AUTOSAR XML (schema 3.1.2)
package /Components/SWC_UsThrMT
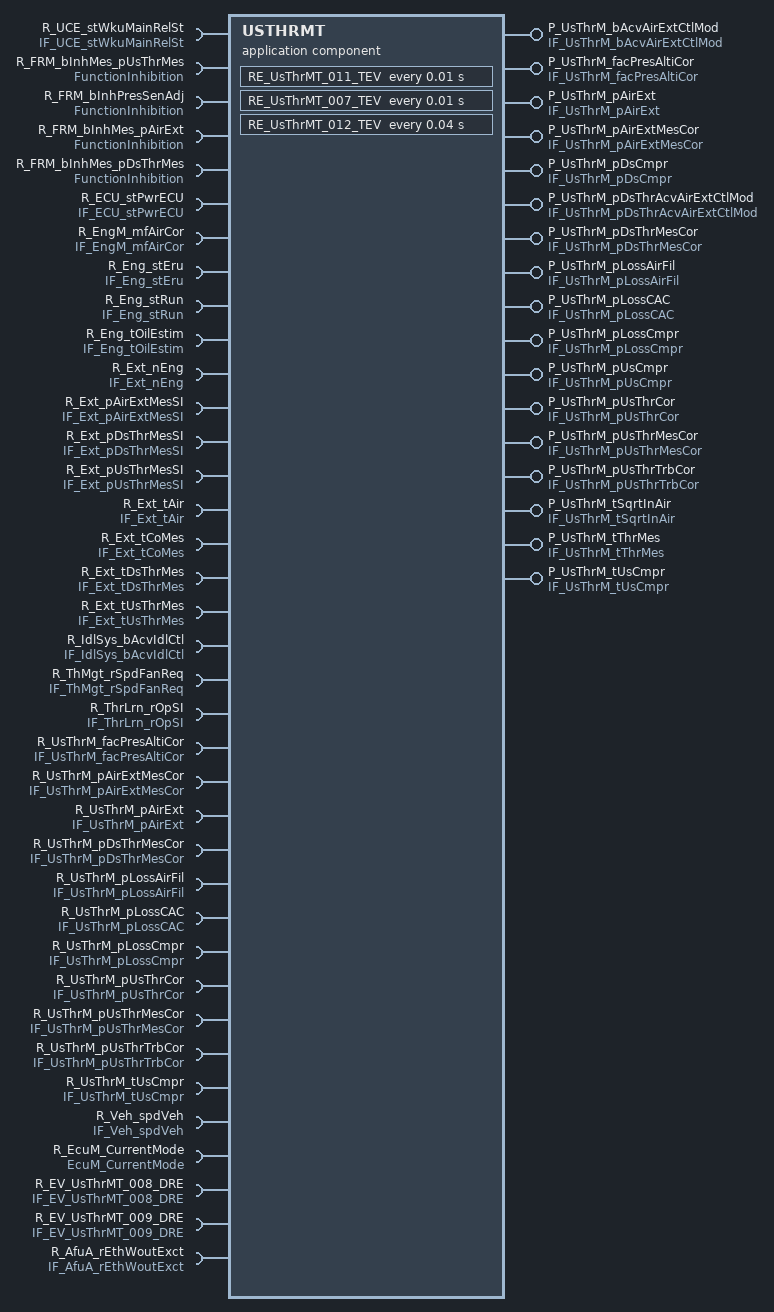
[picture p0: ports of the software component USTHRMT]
  application software component type USTHRMT  # UsThrMT
    5 x require port:
      R_UCE_stWkuMainRelSt: required-interface=IF_UCE_stWkuMainRelSt
      R_FRM_bInhMes_pUsThrMes: required-interface=FunctionInhibition
      R_FRM_bInhPresSenAdj: required-interface=FunctionInhibition
      R_FRM_bInhMes_pAirExt: required-interface=FunctionInhibition
      R_FRM_bInhMes_pDsThrMes: required-interface=FunctionInhibition
    17 x provide port:
      P_UsThrM_bAcvAirExtCtlMod: unqueued-sender-com-spec{data-element=UsThrM_bAcvAirExtCtlMod, can-invalidate=false, init-value=ConstantValue}, provided-interface=IF_UsThrM_bAcvAirExtCtlMod
      P_UsThrM_facPresAltiCor: unqueued-sender-com-spec{data-element=UsThrM_facPresAltiCor, can-invalidate=false, init-value=ConstantValue1}, provided-interface=IF_UsThrM_facPresAltiCor
      P_UsThrM_pAirExt: unqueued-sender-com-spec{data-element=UsThrM_pAirExt, can-invalidate=false, init-value=ConstantValue3}, provided-interface=IF_UsThrM_pAirExt
      P_UsThrM_pAirExtMesCor: unqueued-sender-com-spec{data-element=UsThrM_pAirExtMesCor, can-invalidate=false, init-value=UInt16InitValue}, provided-interface=IF_UsThrM_pAirExtMesCor
      P_UsThrM_pDsCmpr: unqueued-sender-com-spec{data-element=UsThrM_pDsCmpr, can-invalidate=false, init-value=UInt16InitValue5}, provided-interface=IF_UsThrM_pDsCmpr
      P_UsThrM_pDsThrAcvAirExtCtlMod: unqueued-sender-com-spec{data-element=UsThrM_pDsThrAcvAirExtCtlMod, can-invalidate=false, init-value=UInt16InitValue7}, provided-interface=IF_UsThrM_pDsThrAcvAirExtCtlMod
      P_UsThrM_pDsThrMesCor: unqueued-sender-com-spec{data-element=UsThrM_pDsThrMesCor, can-invalidate=false, init-value=ConstantValue9}, provided-interface=IF_UsThrM_pDsThrMesCor
      P_UsThrM_pLossAirFil: unqueued-sender-com-spec{data-element=UsThrM_pLossAirFil, can-invalidate=false, init-value=UInt16InitValue11}, provided-interface=IF_UsThrM_pLossAirFil
      P_UsThrM_pLossCAC: unqueued-sender-com-spec{data-element=UsThrM_pLossCAC, can-invalidate=false, init-value=ConstantValue13}, provided-interface=IF_UsThrM_pLossCAC
      P_UsThrM_pLossCmpr: unqueued-sender-com-spec{data-element=UsThrM_pLossCmpr, can-invalidate=false, init-value=SInt16InitValue}, provided-interface=IF_UsThrM_pLossCmpr
      P_UsThrM_pUsCmpr: unqueued-sender-com-spec{data-element=UsThrM_pUsCmpr, can-invalidate=false, init-value=ConstantValue15}, provided-interface=IF_UsThrM_pUsCmpr
      P_UsThrM_pUsThrCor: unqueued-sender-com-spec{data-element=UsThrM_pUsThrCor, can-invalidate=false, init-value=ConstantValue17}, provided-interface=IF_UsThrM_pUsThrCor
      P_UsThrM_pUsThrMesCor: unqueued-sender-com-spec{data-element=UsThrM_pUsThrMesCor, can-invalidate=false, init-value=UInt16InitValue19}, provided-interface=IF_UsThrM_pUsThrMesCor
      P_UsThrM_pUsThrTrbCor: unqueued-sender-com-spec{data-element=UsThrM_pUsThrTrbCor, can-invalidate=false, init-value=UInt16InitValue21}, provided-interface=IF_UsThrM_pUsThrTrbCor
      P_UsThrM_tSqrtInAir: unqueued-sender-com-spec{data-element=UsThrM_tSqrtInAir, can-invalidate=false, init-value=ConstantValue23}, provided-interface=IF_UsThrM_tSqrtInAir
      P_UsThrM_tThrMes: unqueued-sender-com-spec{data-element=UsThrM_tThrMes, can-invalidate=false, init-value=ConstantValue25}, provided-interface=IF_UsThrM_tThrMes
      P_UsThrM_tUsCmpr: unqueued-sender-com-spec{data-element=UsThrM_tUsCmpr, can-invalidate=false, init-value=ConstantValue27}, provided-interface=IF_UsThrM_tUsCmpr
    32 x require port:
      R_ECU_stPwrECU: unqueued-receiver-com-spec{data-element=ECU_stPwrECU, init-value=UInt8InitValue, resync-time=0}, required-interface=IF_ECU_stPwrECU
      R_EngM_mfAirCor: unqueued-receiver-com-spec{data-element=EngM_mfAirCor, init-value=ConstantValue29, resync-time=0}, required-interface=IF_EngM_mfAirCor
      R_Eng_stEru: unqueued-receiver-com-spec{data-element=Eng_stEru, init-value=ConstantValue31, resync-time=0}, required-interface=IF_Eng_stEru
      R_Eng_stRun: unqueued-receiver-com-spec{data-element=Eng_stRun, init-value=UInt8InitValue33, resync-time=0}, required-interface=IF_Eng_stRun
      R_Eng_tOilEstim: unqueued-receiver-com-spec{data-element=Eng_tOilEstim, init-value=ConstantValue35, resync-time=0}, required-interface=IF_Eng_tOilEstim
      R_Ext_nEng: unqueued-receiver-com-spec{data-element=Ext_nEng, init-value=ConstantValue37, resync-time=0}, required-interface=IF_Ext_nEng
      R_Ext_pAirExtMesSI: unqueued-receiver-com-spec{data-element=Ext_pAirExtMesSI, init-value=UInt16InitValue39, resync-time=0}, required-interface=IF_Ext_pAirExtMesSI
      R_Ext_pDsThrMesSI: unqueued-receiver-com-spec{data-element=Ext_pDsThrMesSI, init-value=ConstantValue41, resync-time=0}, required-interface=IF_Ext_pDsThrMesSI
      R_Ext_pUsThrMesSI: unqueued-receiver-com-spec{data-element=Ext_pUsThrMesSI, init-value=UInt16InitValue43, resync-time=0}, required-interface=IF_Ext_pUsThrMesSI
      R_Ext_tAir: unqueued-receiver-com-spec{data-element=Ext_tAir, init-value=ConstantValue45, resync-time=0}, required-interface=IF_Ext_tAir
      R_Ext_tCoMes: unqueued-receiver-com-spec{data-element=Ext_tCoMes, init-value=ConstantValue47, resync-time=0}, required-interface=IF_Ext_tCoMes
      R_Ext_tDsThrMes: unqueued-receiver-com-spec{data-element=Ext_tDsThrMes, init-value=ConstantValue49, resync-time=0}, required-interface=IF_Ext_tDsThrMes
      R_Ext_tUsThrMes: unqueued-receiver-com-spec{data-element=Ext_tUsThrMes, init-value=ConstantValue51, resync-time=0}, required-interface=IF_Ext_tUsThrMes
      R_IdlSys_bAcvIdlCtl: unqueued-receiver-com-spec{data-element=IdlSys_bAcvIdlCtl, init-value=ConstantValue53, resync-time=0}, required-interface=IF_IdlSys_bAcvIdlCtl
      R_ThMgt_rSpdFanReq: unqueued-receiver-com-spec{data-element=ThMgt_rSpdFanReq, init-value=ConstantValue55, resync-time=0}, required-interface=IF_ThMgt_rSpdFanReq
      R_ThrLrn_rOpSI: unqueued-receiver-com-spec{data-element=ThrLrn_rOpSI, init-value=ConstantValue57, resync-time=0}, required-interface=IF_ThrLrn_rOpSI
      R_UsThrM_facPresAltiCor: unqueued-receiver-com-spec{data-element=UsThrM_facPresAltiCor, init-value=ConstantValue59, resync-time=0}, required-interface=IF_UsThrM_facPresAltiCor
      R_UsThrM_pAirExtMesCor: unqueued-receiver-com-spec{data-element=UsThrM_pAirExtMesCor, init-value=UInt16InitValue, resync-time=0}, required-interface=IF_UsThrM_pAirExtMesCor
      R_UsThrM_pAirExt: unqueued-receiver-com-spec{data-element=UsThrM_pAirExt, init-value=ConstantValue61, resync-time=0}, required-interface=IF_UsThrM_pAirExt
      R_UsThrM_pDsThrMesCor: unqueued-receiver-com-spec{data-element=UsThrM_pDsThrMesCor, init-value=ConstantValue63, resync-time=0}, required-interface=IF_UsThrM_pDsThrMesCor
      R_UsThrM_pLossAirFil: unqueued-receiver-com-spec{data-element=UsThrM_pLossAirFil, init-value=UInt16InitValue65, resync-time=0}, required-interface=IF_UsThrM_pLossAirFil
      R_UsThrM_pLossCAC: unqueued-receiver-com-spec{data-element=UsThrM_pLossCAC, init-value=ConstantValue67, resync-time=0}, required-interface=IF_UsThrM_pLossCAC
      R_UsThrM_pLossCmpr: unqueued-receiver-com-spec{data-element=UsThrM_pLossCmpr, init-value=SInt16InitValue, resync-time=0}, required-interface=IF_UsThrM_pLossCmpr
      R_UsThrM_pUsThrCor: unqueued-receiver-com-spec{data-element=UsThrM_pUsThrCor, init-value=ConstantValue69, resync-time=0}, required-interface=IF_UsThrM_pUsThrCor
      R_UsThrM_pUsThrMesCor: unqueued-receiver-com-spec{data-element=UsThrM_pUsThrMesCor, init-value=UInt16InitValue71, resync-time=0}, required-interface=IF_UsThrM_pUsThrMesCor
      R_UsThrM_pUsThrTrbCor: unqueued-receiver-com-spec{data-element=UsThrM_pUsThrTrbCor, init-value=UInt16InitValue73, resync-time=0}, required-interface=IF_UsThrM_pUsThrTrbCor
      R_UsThrM_tUsCmpr: unqueued-receiver-com-spec{data-element=UsThrM_tUsCmpr, init-value=ConstantValue75, resync-time=0}, required-interface=IF_UsThrM_tUsCmpr
      R_Veh_spdVeh: unqueued-receiver-com-spec{data-element=Veh_spdVeh, init-value=ConstantValue77, resync-time=0}, required-interface=IF_Veh_spdVeh
      R_EcuM_CurrentMode: required-interface=EcuM_CurrentMode
      R_EV_UsThrMT_008_DRE: unqueued-receiver-com-spec{data-element=EV_UsThrMT_008_DRE, init-value=UInt8InitValue79, resync-time=0}, required-interface=IF_EV_UsThrMT_008_DRE
      R_EV_UsThrMT_009_DRE: unqueued-receiver-com-spec{data-element=EV_UsThrMT_009_DRE, init-value=UInt8InitValue81, resync-time=0}, required-interface=IF_EV_UsThrMT_009_DRE
      R_AfuA_rEthWoutExct: unqueued-receiver-com-spec{data-element=AfuA_rEthWoutExct, init-value=ConstantValue2, resync-time=0}, required-interface=IF_AfuA_rEthWoutExct
  56 x constant specification:
    ConstantValue
      value:
        boolean literal ConstantValue: type=DT_UsThrM_bAcvAirExtCtlMod, value=false
    ConstantValue1
      value:
        integer literal ConstantValue1: type=DT_UsThrM_facPresAltiCor, value=0
    ConstantValue13
      value:
        integer literal ConstantValue13: type=DT_UsThrM_pLossCAC, value=0
    ConstantValue15
      value:
        integer literal ConstantValue15: type=DT_UsThrM_pUsCmpr, value=0
    ConstantValue17
      value:
        integer literal ConstantValue17: type=DT_UsThrM_pUsThrCor, value=0
    ConstantValue2
      value:
        integer literal ConstantValue2: type=DT_AfuA_rEthWoutExct, value=0
    ConstantValue23
      value:
        integer literal ConstantValue23: type=DT_UsThrM_tSqrtInAir, value=120
    ConstantValue25
      value:
        integer literal ConstantValue25: type=DT_UsThrM_tThrMes, value=0
    ConstantValue27
      value:
        integer literal ConstantValue27: type=DT_UsThrM_tUsCmpr, value=0
    ConstantValue29
      value:
        integer literal ConstantValue29: type=DT_EngM_mfAirCor, value=0
    ConstantValue3
      value:
        integer literal ConstantValue3: type=DT_UsThrM_pAirExt, value=0
    ConstantValue31
      value:
        integer literal ConstantValue31: type=DT_Eng_stEru, value=1
    ConstantValue35
      value:
        integer literal ConstantValue35: type=DT_Eng_tOilEstim, value=0
    ConstantValue37
      value:
        integer literal ConstantValue37: type=DT_Ext_nEng, value=0
    ConstantValue41
      value:
        integer literal ConstantValue41: type=DT_Ext_pDsThrMesSI, value=1875
    ConstantValue45
      value:
        integer literal ConstantValue45: type=DT_Ext_tAir, value=20
    ConstantValue47
      value:
        integer literal ConstantValue47: type=DT_Ext_tCoMes, value=20
    ConstantValue49
      value:
        integer literal ConstantValue49: type=DT_Ext_tDsThrMes, value=25
    ConstantValue51
      value:
        integer literal ConstantValue51: type=DT_Ext_tUsThrMes, value=25
    ConstantValue53
      value:
        boolean literal ConstantValue53: type=DT_IdlSys_bAcvIdlCtl, value=false
    ConstantValue55
      value:
        integer literal ConstantValue55: type=DT_ThMgt_rSpdFanReq, value=0
    ConstantValue57
      value:
        integer literal ConstantValue57: type=DT_ThrLrn_rOpSI, value=0
    ConstantValue59
      value:
        integer literal ConstantValue59: type=DT_UsThrM_facPresAltiCor, value=0
    ConstantValue61
      value:
        integer literal ConstantValue61: type=DT_UsThrM_pAirExt, value=0
    ConstantValue63
      value:
        integer literal ConstantValue63: type=DT_UsThrM_pDsThrMesCor, value=0
    ConstantValue67
      value:
        integer literal ConstantValue67: type=DT_UsThrM_pLossCAC, value=0
    ConstantValue69
      value:
        integer literal ConstantValue69: type=DT_UsThrM_pUsThrCor, value=0
    ConstantValue75
      value:
        integer literal ConstantValue75: type=DT_UsThrM_tUsCmpr, value=0
    ConstantValue77
      value:
        integer literal ConstantValue77: type=DT_Veh_spdVeh, value=0
    ConstantValue9
      value:
        integer literal ConstantValue9: type=DT_UsThrM_pDsThrMesCor, value=0
    InitValue_UInt16_0
      value:
        integer literal InitValue_UInt16_0: type=DT_UsThrM_tiTmrDifPres_irv, value=0
    InitValue_UInt16_085
      value:
        integer literal InitValue_UInt16_085: type=DT_UsThrM_ctUpdAirExtPresCut_irv, value=0
    InitValue_UInt16_087
      value:
        integer literal InitValue_UInt16_087: type=DT_UsThrM_ctUpdAirExtPresIdl_irv, value=0
    InitValue_UInt16_089
      value:
        integer literal InitValue_UInt16_089: type=DT_UsThrM_pUsThrMesSIFil_irv, value=0
    InitValue_UInt16_091
      value:
        integer literal InitValue_UInt16_091: type=DT_UsThrM_pAirExtMesSIFil_irv, value=0
    InitValue_UInt16_093
      value:
        integer literal InitValue_UInt16_093: type=DT_UsThrM_ctUpdAirExtPresRun_irv, value=0
    InitValue_UInt16_095
      value:
        integer literal InitValue_UInt16_095: type=DT_UsThrM_pDsThrMesSIFil_irv, value=0
    InitValue_UInt16_097
      value:
        integer literal InitValue_UInt16_097: type=DT_UsThrM_pAirExtRaw_irv, value=0
    InitValue_UInt16_099
      value:
        integer literal InitValue_UInt16_099: type=DT_UsThrM_ctUpdAirExtPresStall_irv, value=0
    InitValue_UInt32_0
      value:
        integer literal InitValue_UInt32_0: type=DT_UsThrM_tUndHo_irv, value=0
    SInt16InitValue
      value:
        integer literal SInt16InitValue: type=DT_UsThrM_pLossCmpr, value=-32768
    UInt16InitValue
      value:
        integer literal UInt16InitValue: type=DT_UsThrM_pAirExtMesCor, value=0
    UInt16InitValue11
      value:
        integer literal UInt16InitValue11: type=DT_UsThrM_pLossAirFil, value=0
    UInt16InitValue19
      value:
        integer literal UInt16InitValue19: type=DT_UsThrM_pUsThrMesCor, value=0
    UInt16InitValue21
      value:
        integer literal UInt16InitValue21: type=DT_UsThrM_pUsThrTrbCor, value=0
    UInt16InitValue39
      value:
        integer literal UInt16InitValue39: type=DT_Ext_pAirExtMesSI, value=0
    UInt16InitValue43
      value:
        integer literal UInt16InitValue43: type=DT_Ext_pUsThrMesSI, value=0
    UInt16InitValue5
      value:
        integer literal UInt16InitValue5: type=DT_UsThrM_pDsCmpr, value=0
    UInt16InitValue65
      value:
        integer literal UInt16InitValue65: type=DT_UsThrM_pLossAirFil, value=0
    UInt16InitValue7
      value:
        integer literal UInt16InitValue7: type=DT_UsThrM_pDsThrAcvAirExtCtlMod, value=0
    UInt16InitValue71
      value:
        integer literal UInt16InitValue71: type=DT_UsThrM_pUsThrMesCor, value=0
    UInt16InitValue73
      value:
        integer literal UInt16InitValue73: type=DT_UsThrM_pUsThrTrbCor, value=0
    UInt8InitValue
      value:
        integer literal UInt8InitValue: type=DT_ECU_stPwrECU, value=1
    UInt8InitValue33
      value:
        integer literal UInt8InitValue33: type=DT_Eng_stRun, value=1
    UInt8InitValue79
      value:
        integer literal UInt8InitValue79: type=DT_EV_UsThrMT_008_DRE, value=0
    UInt8InitValue81
      value:
        integer literal UInt8InitValue81: type=DT_EV_UsThrMT_009_DRE, value=0
  internal behavior IB_UsThrMT: component=USTHRMT
    timing event EV_UsThrMT_011_TEV: mode-dependency=dependent-on-mode=[R_UCE_stWkuMainRelSt.RCD_stWkuMainRelSt.PreMainWakeUp, R_UCE_stWkuMainRelSt.RCD_stWkuMainRelSt.PostMainWakeUp, R_UCE_stWkuMainRelSt.RCD_stWkuMainRelSt.Invalid], start-on-event=RE_UsThrMT_011_TEV, period=0.01
    data received event EV_UsThrMT_009_DRE: mode-dependency=dependent-on-mode=[R_UCE_stWkuMainRelSt.RCD_stWkuMainRelSt.PreMainWakeUp, R_UCE_stWkuMainRelSt.RCD_stWkuMainRelSt.PostMainWakeUp, R_UCE_stWkuMainRelSt.RCD_stWkuMainRelSt.Invalid], start-on-event=RE_UsThrMT_009_DRE, data=R_EV_UsThrMT_009_DRE.EV_UsThrMT_009_DRE
    mode switch event EV_UsThrMT_001_MSE: start-on-event=RE_UsThrMT_001_MSE, activation=ENTRY, mode=R_EcuM_CurrentMode.currentMode.RUN
    5 x timing event, all with mode-dependency=dependent-on-mode=[R_UCE_stWkuMainRelSt.RCD_stWkuMainRelSt.PreMainWakeUp, R_UCE_stWkuMainRelSt.RCD_stWkuMainRelSt.PostMainWakeUp, R_UCE_stWkuMainRelSt.RCD_stWkuMainRelSt.Invalid]:
      EV_UsThrMT_005_TEV: start-on-event=RE_UsThrMT_005_TEV, period=0.04
      EV_UsThrMT_008_TEV: start-on-event=RE_UsThrMT_008_TEV, period=0.04
      EV_UsThrMT_006_TEV: start-on-event=RE_UsThrMT_006_TEV, period=0.01
      EV_UsThrMT_002_TEV: start-on-event=RE_UsThrMT_002_TEV, period=0.01
      EV_UsThrMT_010_TEV: start-on-event=RE_UsThrMT_010_TEV, period=0.01
    data received event EV_UsThrMT_008_DRE: mode-dependency=dependent-on-mode=[R_UCE_stWkuMainRelSt.RCD_stWkuMainRelSt.PreMainWakeUp, R_UCE_stWkuMainRelSt.RCD_stWkuMainRelSt.PostMainWakeUp, R_UCE_stWkuMainRelSt.RCD_stWkuMainRelSt.Invalid], start-on-event=RE_UsThrMT_008_DRE, data=R_EV_UsThrMT_008_DRE.EV_UsThrMT_008_DRE
    mode switch event EV_UsThrMT_004_MSE: start-on-event=RE_UsThrMT_004_MSE, activation=ENTRY, mode=R_EcuM_CurrentMode.currentMode.RUN
    timing event EV_UsThrMT_007_TEV: mode-dependency=dependent-on-mode=[R_UCE_stWkuMainRelSt.RCD_stWkuMainRelSt.PreMainWakeUp, R_UCE_stWkuMainRelSt.RCD_stWkuMainRelSt.PostMainWakeUp, R_UCE_stWkuMainRelSt.RCD_stWkuMainRelSt.Invalid], start-on-event=RE_UsThrMT_007_TEV, period=0.01
    timing event EV_UsThrMT_012_TEV: mode-dependency=dependent-on-mode=[R_UCE_stWkuMainRelSt.RCD_stWkuMainRelSt.PreMainWakeUp, R_UCE_stWkuMainRelSt.RCD_stWkuMainRelSt.PostMainWakeUp, R_UCE_stWkuMainRelSt.RCD_stWkuMainRelSt.Invalid], start-on-event=RE_UsThrMT_012_TEV, period=0.04
    10 x inter runnable variable, all with sw-calibration-access=READ-WRITE, communication-approach=EXPLICIT:
      UsThrM_ctUpdAirExtPresIdl_irv: type=DT_UsThrM_ctUpdAirExtPresIdl_irv, init-value=InitValue_UInt16_087
      UsThrM_pDsThrMesSIFil_irv: type=DT_UsThrM_pDsThrMesSIFil_irv, init-value=InitValue_UInt16_095
      UsThrM_ctUpdAirExtPresRun_irv: type=DT_UsThrM_ctUpdAirExtPresRun_irv, init-value=InitValue_UInt16_093
      UsThrM_tUndHo_irv: type=DT_UsThrM_tUndHo_irv, init-value=InitValue_UInt32_0
      UsThrM_ctUpdAirExtPresStall_irv: type=DT_UsThrM_ctUpdAirExtPresStall_irv, init-value=InitValue_UInt16_099
      UsThrM_pAirExtMesSIFil_irv: type=DT_UsThrM_pAirExtMesSIFil_irv, init-value=InitValue_UInt16_091
      UsThrM_tiTmrDifPres_irv: type=DT_UsThrM_tiTmrDifPres_irv, init-value=InitValue_UInt16_0
      UsThrM_pUsThrMesSIFil_irv: type=DT_UsThrM_pUsThrMesSIFil_irv, init-value=InitValue_UInt16_089
      UsThrM_pAirExtRaw_irv: type=DT_UsThrM_pAirExtRaw_irv, init-value=InitValue_UInt16_097
      UsThrM_ctUpdAirExtPresCut_irv: type=DT_UsThrM_ctUpdAirExtPresCut_irv, init-value=InitValue_UInt16_085
    12 x runnable:
      RE_UsThrMT_008_TEV
        data receive point dr_EngM_mfAirCor: data-element=R_EngM_mfAirCor.EngM_mfAirCor
        data send point DSP_P_UsThrM_pAirExt_UsThrM_pAirExt: data-element=P_UsThrM_pAirExt.UsThrM_pAirExt
        data send point ds_UsThrM_pLossAirFil: data-element=P_UsThrM_pLossAirFil.UsThrM_pLossAirFil
      RE_UsThrMT_010_TEV: read-variable=[UsThrM_ctUpdAirExtPresIdl_irv, UsThrM_ctUpdAirExtPresCut_irv, UsThrM_ctUpdAirExtPresRun_irv, UsThrM_ctUpdAirExtPresStall_irv, UsThrM_pAirExtRaw_irv], written-variable=[UsThrM_ctUpdAirExtPresIdl_irv, UsThrM_ctUpdAirExtPresCut_irv, UsThrM_ctUpdAirExtPresRun_irv, UsThrM_ctUpdAirExtPresStall_irv, UsThrM_pAirExtRaw_irv]
        13 x data receive point:
          dr_IdlSys_bAcvIdlCtl: data-element=R_IdlSys_bAcvIdlCtl.IdlSys_bAcvIdlCtl
          dr_ECU_stPwrECU: data-element=R_ECU_stPwrECU.ECU_stPwrECU
          dr_UsThrM_pUsThrMesCor: data-element=R_UsThrM_pUsThrMesCor.UsThrM_pUsThrMesCor
          dr_Eng_stEru: data-element=R_Eng_stEru.Eng_stEru
          dr_UsThrM_pLossCmpr: data-element=R_UsThrM_pLossCmpr.UsThrM_pLossCmpr
          dr_UsThrM_pDsThrMesCor: data-element=R_UsThrM_pDsThrMesCor.UsThrM_pDsThrMesCor
          dr_Eng_stRun: data-element=R_Eng_stRun.Eng_stRun
          dr_UsThrM_pLossAirFil: data-element=R_UsThrM_pLossAirFil.UsThrM_pLossAirFil
          dr_Ext_nEng: data-element=R_Ext_nEng.Ext_nEng
          dr_UsThrM_pAirExt: data-element=R_UsThrM_pAirExt.UsThrM_pAirExt
          dr_ThrLrn_rOpSI: data-element=R_ThrLrn_rOpSI.ThrLrn_rOpSI
          dr_UsThrM_pLossCAC: data-element=R_UsThrM_pLossCAC.UsThrM_pLossCAC
          dr_UsThrM_pAirExtMesCor: data-element=R_UsThrM_pAirExtMesCor.UsThrM_pAirExtMesCor
        data send point ds_UsThrM_facPresAltiCor: data-element=P_UsThrM_facPresAltiCor.UsThrM_facPresAltiCor
        sync call ssp_FRM_bInhMes_pDsThrMes: operation=R_FRM_bInhMes_pDsThrMes.GetFunctionPermission
        sync call ssp_FRM_bInhMes_pAirExt: operation=R_FRM_bInhMes_pAirExt.GetFunctionPermission
        sync call ssp_FRM_bInhMes_pUsThrMes: operation=R_FRM_bInhMes_pUsThrMes.GetFunctionPermission
      RE_UsThrMT_006_TEV
        4 x data receive point:
          dr_UsThrM_pLossAirFil: data-element=R_UsThrM_pLossAirFil.UsThrM_pLossAirFil
          dr_EngM_mfAirCor: data-element=R_EngM_mfAirCor.EngM_mfAirCor
          dr_UsThrM_pAirExt: data-element=R_UsThrM_pAirExt.UsThrM_pAirExt
          dr_UsThrM_pUsThrMesCor: data-element=R_UsThrM_pUsThrMesCor.UsThrM_pUsThrMesCor
        5 x data send point:
          ds_UsThrM_pLossCAC: data-element=P_UsThrM_pLossCAC.UsThrM_pLossCAC
          ds_UsThrM_pLossCmpr: data-element=P_UsThrM_pLossCmpr.UsThrM_pLossCmpr
          ds_UsThrM_pDsCmpr: data-element=P_UsThrM_pDsCmpr.UsThrM_pDsCmpr
          ds_UsThrM_pUsCmpr: data-element=P_UsThrM_pUsCmpr.UsThrM_pUsCmpr
          ds_UsThrM_pUsThrTrbCor: data-element=P_UsThrM_pUsThrTrbCor.UsThrM_pUsThrTrbCor
        sync call ssp_FRM_bInhMes_pUsThrMes: operation=R_FRM_bInhMes_pUsThrMes.GetFunctionPermission
      RE_UsThrMT_002_TEV: read-variable=[UsThrM_pDsThrMesSIFil_irv, UsThrM_pAirExtMesSIFil_irv, UsThrM_tiTmrDifPres_irv, UsThrM_pUsThrMesSIFil_irv], written-variable=[UsThrM_pDsThrMesSIFil_irv, UsThrM_pAirExtMesSIFil_irv, UsThrM_tiTmrDifPres_irv, UsThrM_pUsThrMesSIFil_irv]
        4 x data receive point:
          dr_Ext_pDsThrMesSI: data-element=R_Ext_pDsThrMesSI.Ext_pDsThrMesSI
          dr_Ext_pAirExtMesSI: data-element=R_Ext_pAirExtMesSI.Ext_pAirExtMesSI
          dr_Eng_stEru: data-element=R_Eng_stEru.Eng_stEru
          dr_Ext_pUsThrMesSI: data-element=R_Ext_pUsThrMesSI.Ext_pUsThrMesSI
        data send point ds_UsThrM_pAirExtMesCor: data-element=P_UsThrM_pAirExtMesCor.UsThrM_pAirExtMesCor
        data send point ds_UsThrM_pDsThrMesCor: data-element=P_UsThrM_pDsThrMesCor.UsThrM_pDsThrMesCor
        data send point ds_UsThrM_pUsThrMesCor: data-element=P_UsThrM_pUsThrMesCor.UsThrM_pUsThrMesCor
        sync call ssp_FRM_bInhPresSenAdj: operation=R_FRM_bInhPresSenAdj.GetFunctionPermission
      RE_UsThrMT_004_MSE: written-variable=[UsThrM_tUndHo_irv, UsThrM_ctUpdAirExtPresRun_irv, UsThrM_ctUpdAirExtPresIdl_irv, UsThrM_ctUpdAirExtPresCut_irv, UsThrM_ctUpdAirExtPresStall_irv, UsThrM_pAirExtRaw_irv]
        6 x data receive point:
          dr_UsThrM_pAirExt: data-element=R_UsThrM_pAirExt.UsThrM_pAirExt
          dr_Ext_tUsThrMes: data-element=R_Ext_tUsThrMes.Ext_tUsThrMes
          dr_Ext_tDsThrMes: data-element=R_Ext_tDsThrMes.Ext_tDsThrMes
          dr_UsThrM_pUsThrTrbCor: data-element=R_UsThrM_pUsThrTrbCor.UsThrM_pUsThrTrbCor
          dr_UsThrM_pUsThrMesCor: data-element=R_UsThrM_pUsThrMesCor.UsThrM_pUsThrMesCor
          dr_UsThrM_pAirExtMesCor: data-element=R_UsThrM_pAirExtMesCor.UsThrM_pAirExtMesCor
        14 x data send point:
          ds_UsThrM_pLossCmpr: data-element=P_UsThrM_pLossCmpr.UsThrM_pLossCmpr
          ds_UsThrM_pUsThrCor: data-element=P_UsThrM_pUsThrCor.UsThrM_pUsThrCor
          ds_UsThrM_pUsThrTrbCor: data-element=P_UsThrM_pUsThrTrbCor.UsThrM_pUsThrTrbCor
          ds_UsThrM_tThrMes: data-element=P_UsThrM_tThrMes.UsThrM_tThrMes
          ds_UsThrM_bAcvAirExtCtlMod: data-element=P_UsThrM_bAcvAirExtCtlMod.UsThrM_bAcvAirExtCtlMod
          ds_UsThrM_tSqrtInAir: data-element=P_UsThrM_tSqrtInAir.UsThrM_tSqrtInAir
          ds_UsThrM_pDsThrAcvAirExtCtlMod: data-element=P_UsThrM_pDsThrAcvAirExtCtlMod.UsThrM_pDsThrAcvAirExtCtlMod
          ds_UsThrM_pLossCAC: data-element=P_UsThrM_pLossCAC.UsThrM_pLossCAC
          ds_UsThrM_tUsCmpr: data-element=P_UsThrM_tUsCmpr.UsThrM_tUsCmpr
          ds_UsThrM_facPresAltiCor: data-element=P_UsThrM_facPresAltiCor.UsThrM_facPresAltiCor
          ds_UsThrM_pUsCmpr: data-element=P_UsThrM_pUsCmpr.UsThrM_pUsCmpr
          DSP_P_UsThrM_pAirExt_UsThrM_pAirExt: data-element=P_UsThrM_pAirExt.UsThrM_pAirExt
          ds_UsThrM_pLossAirFil: data-element=P_UsThrM_pLossAirFil.UsThrM_pLossAirFil
          ds_UsThrM_pDsCmpr: data-element=P_UsThrM_pDsCmpr.UsThrM_pDsCmpr
        sync call ssp_FRM_bInhMes_pAirExt: operation=R_FRM_bInhMes_pAirExt.GetFunctionPermission
      RE_UsThrMT_001_MSE: written-variable=[UsThrM_pAirExtMesSIFil_irv, UsThrM_pDsThrMesSIFil_irv, UsThrM_pUsThrMesSIFil_irv, UsThrM_tiTmrDifPres_irv]
        data receive point dr_Ext_pUsThrMesSI: data-element=R_Ext_pUsThrMesSI.Ext_pUsThrMesSI
        data receive point dr_Ext_pAirExtMesSI: data-element=R_Ext_pAirExtMesSI.Ext_pAirExtMesSI
        data receive point dr_Ext_pDsThrMesSI: data-element=R_Ext_pDsThrMesSI.Ext_pDsThrMesSI
        data send point ds_UsThrM_pAirExtMesCor: data-element=P_UsThrM_pAirExtMesCor.UsThrM_pAirExtMesCor
        data send point ds_UsThrM_pDsThrMesCor: data-element=P_UsThrM_pDsThrMesCor.UsThrM_pDsThrMesCor
        data send point ds_UsThrM_pUsThrMesCor: data-element=P_UsThrM_pUsThrMesCor.UsThrM_pUsThrMesCor
      RE_UsThrMT_011_TEV
        5 x data receive point:
          dr_UsThrM_pUsThrTrbCor: data-element=R_UsThrM_pUsThrTrbCor.UsThrM_pUsThrTrbCor
          dr_Eng_stEru: data-element=R_Eng_stEru.Eng_stEru
          dr_UsThrM_pLossAirFil: data-element=R_UsThrM_pLossAirFil.UsThrM_pLossAirFil
          dr_UsThrM_pAirExt: data-element=R_UsThrM_pAirExt.UsThrM_pAirExt
          dr_UsThrM_pUsThrCor: data-element=R_UsThrM_pUsThrCor.UsThrM_pUsThrCor
      RE_UsThrMT_009_DRE: written-variable=UsThrM_ctUpdAirExtPresStall_irv
        data receive point dr_EV_UsThrMT_009_DRE: data-element=R_EV_UsThrMT_009_DRE.EV_UsThrMT_009_DRE
      RE_UsThrMT_008_DRE
        data receive point dr_EngM_mfAirCor: data-element=R_EngM_mfAirCor.EngM_mfAirCor
        data receive point dr_EV_UsThrMT_008_DRE: data-element=R_EV_UsThrMT_008_DRE.EV_UsThrMT_008_DRE
        data send point ds_UsThrM_pLossAirFil: data-element=P_UsThrM_pLossAirFil.UsThrM_pLossAirFil
      RE_UsThrMT_005_TEV: read-variable=UsThrM_tUndHo_irv, written-variable=UsThrM_tUndHo_irv
        6 x data receive point:
          dr_Eng_tOilEstim: data-element=R_Eng_tOilEstim.Eng_tOilEstim
          dr_Veh_spdVeh: data-element=R_Veh_spdVeh.Veh_spdVeh
          dr_ThMgt_rSpdFanReq: data-element=R_ThMgt_rSpdFanReq.ThMgt_rSpdFanReq
          dr_Ext_tCoMes: data-element=R_Ext_tCoMes.Ext_tCoMes
          dr_Ext_tAir: data-element=R_Ext_tAir.Ext_tAir
          dr_UsThrM_tUsCmpr: data-element=R_UsThrM_tUsCmpr.UsThrM_tUsCmpr
      RE_UsThrMT_007_TEV
        4 x data receive point:
          dr_UsThrM_pDsThrMesCor: data-element=R_UsThrM_pDsThrMesCor.UsThrM_pDsThrMesCor
          dr_UsThrM_facPresAltiCor: data-element=R_UsThrM_facPresAltiCor.UsThrM_facPresAltiCor
          dr_Ext_nEng: data-element=R_Ext_nEng.Ext_nEng
          dr_AfuA_rEthWoutExct: data-element=R_AfuA_rEthWoutExct.AfuA_rEthWoutExct
        data send point ds_UsThrM_pDsThrAcvAirExtCtlMod: data-element=P_UsThrM_pDsThrAcvAirExtCtlMod.UsThrM_pDsThrAcvAirExtCtlMod
        data send point ds_UsThrM_bAcvAirExtCtlMod: data-element=P_UsThrM_bAcvAirExtCtlMod.UsThrM_bAcvAirExtCtlMod
      RE_UsThrMT_012_TEV
        data receive point dr_Ext_tUsThrMes: data-element=R_Ext_tUsThrMes.Ext_tUsThrMes
        data receive point dr_Ext_tDsThrMes: data-element=R_Ext_tDsThrMes.Ext_tDsThrMes
        data send point ds_UsThrM_tThrMes: data-element=P_UsThrM_tThrMes.UsThrM_tThrMes
        data send point ds_UsThrM_tSqrtInAir: data-element=P_UsThrM_tSqrtInAir.UsThrM_tSqrtInAir
  swc implementation Imp_UsThrMT: code-generator=Real-Time Workshop Embedded Coder 5.5 (R2010a) 25-Jan-2010, programming-language=C, behavior=IB_UsThrMT
    code-descriptors:
      code CodeDescriptor: type=SRC
        12 x xfile:
          UsThrMT_nvm_h: url=UsThrMT_nvm.h
          UsThrMT_MemMap_h: url=UsThrMT_MemMap.h
          UsThrMT_types_h: url=UsThrMT_types.h
          UsThrMT_import_h: url=UsThrMT_import.h
          UsThrMT_Version_h: url=UsThrMT_Version.h
          UsThrMT_c: url=UsThrMT.c
          UsThrMT_data_c: url=UsThrMT_data.c
          UsThrMT_h: url=UsThrMT.h
          UsThrMT_Version_c: url=UsThrMT_Version.c
          UsThrMT_private_h: url=UsThrMT_private.h
          UsThrMT_nvm_c: url=UsThrMT_nvm.c
          UsThrMT_Def_c: url=UsThrMT_Def.c
package /Components/SWC_UsThrMT/UsThrMT_IRVDatatypes
  11 x integer type:
    DT_UsThrM_ctUpdAirExtPresCut_irv: base-type=uint16, lower-limit=0, upper-limit=65535
    DT_UsThrM_ctUpdAirExtPresIdl_irv: base-type=uint16, lower-limit=0, upper-limit=65535
    DT_UsThrM_ctUpdAirExtPresRun_irv: base-type=uint16, lower-limit=0, upper-limit=65535
    DT_UsThrM_ctUpdAirExtPresStall_irv: base-type=uint16, lower-limit=0, upper-limit=65535
    DT_UsThrM_pAirExtMesSIFil_irv: base-type=uint16, lower-limit=0, upper-limit=65535
    DT_UsThrM_pAirExtRaw_irv: base-type=uint16, lower-limit=0, upper-limit=65535
    DT_UsThrM_pDifPresRefDsThr_irv: base-type=int16, lower-limit=-32768, upper-limit=32767
    DT_UsThrM_pDsThrMesSIFil_irv: base-type=uint16, lower-limit=0, upper-limit=65535
    DT_UsThrM_pUsThrMesSIFil_irv: base-type=uint16, lower-limit=0, upper-limit=65535
    DT_UsThrM_tiTmrDifPres_irv: base-type=uint16, lower-limit=0, upper-limit=65535
    DT_UsThrM_tUndHo_irv: base-type=uint32, lower-limit=0, upper-limit=4294967295
